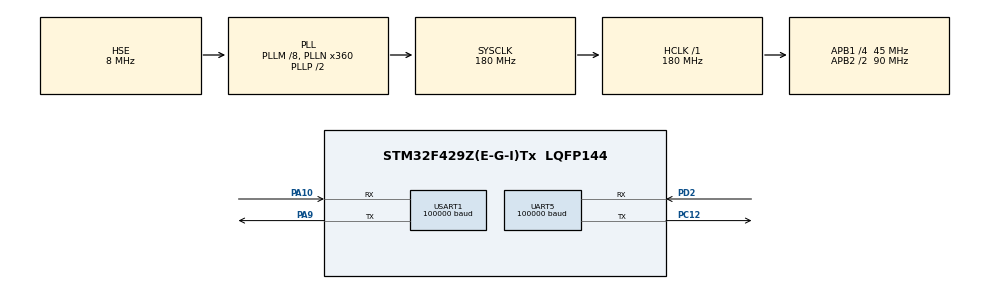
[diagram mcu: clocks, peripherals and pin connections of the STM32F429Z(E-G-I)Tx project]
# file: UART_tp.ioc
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Mcu.Family=STM32F4
Mcu.Name=STM32F429Z(E-G-I)Tx
Mcu.Package=LQFP144
NVIC.PriorityGroup=NVIC_PRIORITYGROUP_4
NVIC.UART5_IRQn=true\:0\:0\:false
NVIC.USART1_IRQn=true\:0\:0\:false
PA10.Mode=Asynchronous
PA10.Signal=USART1_RX
PA9.Mode=Asynchronous
PA9.Signal=USART1_TX
PC12.Mode=Asynchronous
PC12.Signal=UART5_TX
PD2.Mode=Asynchronous
PD2.Signal=UART5_RX
PH0/OSC_IN.Mode=HSE-External-Oscillator
PH0/OSC_IN.Signal=RCC_OSC_IN
PH1/OSC_OUT.Mode=HSE-External-Oscillator
PH1/OSC_OUT.Signal=RCC_OSC_OUT
ProjectManager.TargetToolchain=MDK-ARM V5
RCC.48MHZClocksFreq_Value=90000000
RCC.AHBFreq_Value=180000000
RCC.APB1CLKDivider=RCC_HCLK_DIV4
RCC.APB1Freq_Value=45000000
RCC.APB1TimFreq_Value=90000000
RCC.APB2CLKDivider=RCC_HCLK_DIV2
RCC.APB2Freq_Value=90000000
RCC.APB2TimFreq_Value=180000000
RCC.CortexFreq_Value=180000000
RCC.HCLKFreq_Value=180000000
RCC.HSE_VALUE=8000000
RCC.HSI_VALUE=16000000
RCC.LSE_VALUE=32768
RCC.PLLM=8
RCC.PLLN=360
RCC.PLLSourceVirtual=RCC_PLLSOURCE_HSE
RCC.SYSCLKFreq_VALUE=180000000
RCC.SYSCLKSource=RCC_SYSCLKSOURCE_PLLCLK
RCC.VCOOutputFreq_Value=360000000
UART5.BaudRate=100000
UART5.Parity=UART_PARITY_EVEN
UART5.WordLength=UART_WORDLENGTH_9B
USART1.BaudRate=100000
USART1.Parity=UART_PARITY_EVEN
USART1.WordLength=UART_WORDLENGTH_9B
board=UART_tp

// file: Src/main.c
/**
  ******************************************************************************
  * File Name          : main.c
  * Description        : Main program body
  ******************************************************************************
  *
  * COPYRIGHT(c) 2016 STMicroelectronics
  *
  * Redistribution and use in source and binary forms, with or without modification,
  * are permitted provided that the following conditions are met:
  *   1. Redistributions of source code must retain the above copyright notice,
  *      this list of conditions and the following disclaimer.
  *   2. Redistributions in binary form must reproduce the above copyright notice,
  *      this list of conditions and the following disclaimer in the documentation
  *      and/or other materials provided with the distribution.
  *   3. Neither the name of STMicroelectronics nor the names of its contributors
  *      may be used to endorse or promote products derived from this software
  *      without specific prior written permission.
  *
  * THIS SOFTWARE IS PROVIDED BY THE COPYRIGHT HOLDERS AND CONTRIBUTORS "AS IS"
  * AND ANY EXPRESS OR IMPLIED WARRANTIES, INCLUDING, BUT NOT LIMITED TO, THE
  * IMPLIED WARRANTIES OF MERCHANTABILITY AND FITNESS FOR A PARTICULAR PURPOSE ARE
  * DISCLAIMED. IN NO EVENT SHALL THE COPYRIGHT HOLDER OR CONTRIBUTORS BE LIABLE
  * FOR ANY DIRECT, INDIRECT, INCIDENTAL, SPECIAL, EXEMPLARY, OR CONSEQUENTIAL
  * DAMAGES (INCLUDING, BUT NOT LIMITED TO, PROCUREMENT OF SUBSTITUTE GOODS OR
  * SERVICES; LOSS OF USE, DATA, OR PROFITS; OR BUSINESS INTERRUPTION) HOWEVER
  * CAUSED AND ON ANY THEORY OF LIABILITY, WHETHER IN CONTRACT, STRICT LIABILITY,
  * OR TORT (INCLUDING NEGLIGENCE OR OTHERWISE) ARISING IN ANY WAY OUT OF THE USE
  * OF THIS SOFTWARE, EVEN IF ADVISED OF THE POSSIBILITY OF SUCH DAMAGE.
  *
  ******************************************************************************
  */
#include "stm32f4xx_hal.h"

UART_HandleTypeDef huart5;
UART_HandleTypeDef huart1;

/* USER CODE BEGIN PV */
/* Private variables ---------------------------------------------------------*/

/* USER CODE END PV */

void SystemClock_Config(void);
static void MX_GPIO_Init(void);
static void MX_UART5_Init(void);
static void MX_USART1_UART_Init(void);

#define SIZE 5
uint8_t  UART1_Tx[SIZE] = {0x06, 0x16, 0x26 , 0x36, 0x46} , UART1_Rx[SIZE] , UART5_Tx[SIZE] = {0x09, 0x19, 0x29 , 0x39, 0x49} , UART5_Rx[SIZE] ;
HAL_StatusTypeDef UART1_Tx_Status, UART1_Rx_Status, UART5_Tx_Status, UART5_Rx_Status;
/* USER CODE BEGIN PFP */
/* Private function prototypes -----------------------------------------------*/

/* USER CODE END PFP */

int main(void)
{

  /* MCU Configuration----------------------------------------------------------*/

  /* Reset of all peripherals, Initializes the Flash interface and the Systick. */
  HAL_Init();

  /* Configure the system clock */
  SystemClock_Config();

  /* Initialize all configured peripherals */
  MX_GPIO_Init();
  MX_UART5_Init();
  MX_USART1_UART_Init();

  /* Infinite loop */
  /* USER CODE BEGIN WHILE */

//	HAL_StatusTypeDef HAL_UART_Transmit_IT(UART_HandleTypeDef *huart, uint8_t *pData, uint16_t Size)
//  HAL_StatusTypeDef HAL_UART_Receive_IT(UART_HandleTypeDef *huart, uint8_t *pData, uint16_t Size)

  while (1)
  {
  /* USER CODE END WHILE */

			UART1_Tx_Status = HAL_UART_Transmit_IT(&huart1, UART1_Tx, SIZE);
			UART5_Tx_Status = HAL_UART_Transmit_IT(&huart5, UART5_Tx, SIZE);

		//HAL_GPIO_TogglePin(GPIOG , GPIO_PIN_14);

			HAL_Delay(5);

  }

}

/** System Clock Configuration
*/
void SystemClock_Config(void)
{

  RCC_OscInitTypeDef RCC_OscInitStruct;
  RCC_ClkInitTypeDef RCC_ClkInitStruct;

  __PWR_CLK_ENABLE();

  __HAL_PWR_VOLTAGESCALING_CONFIG(PWR_REGULATOR_VOLTAGE_SCALE1);

  RCC_OscInitStruct.OscillatorType = RCC_OSCILLATORTYPE_HSE;
  RCC_OscInitStruct.HSEState = RCC_HSE_ON;
  RCC_OscInitStruct.PLL.PLLState = RCC_PLL_ON;
  RCC_OscInitStruct.PLL.PLLSource = RCC_PLLSOURCE_HSE;
  RCC_OscInitStruct.PLL.PLLM = 8;
  RCC_OscInitStruct.PLL.PLLN = 360;
  RCC_OscInitStruct.PLL.PLLP = RCC_PLLP_DIV2;
  RCC_OscInitStruct.PLL.PLLQ = 4;
  HAL_RCC_OscConfig(&RCC_OscInitStruct);

  HAL_PWREx_ActivateOverDrive();

  RCC_ClkInitStruct.ClockType = RCC_CLOCKTYPE_SYSCLK|RCC_CLOCKTYPE_PCLK1
                              |RCC_CLOCKTYPE_PCLK2;
  RCC_ClkInitStruct.SYSCLKSource = RCC_SYSCLKSOURCE_PLLCLK;
  RCC_ClkInitStruct.AHBCLKDivider = RCC_SYSCLK_DIV1;
  RCC_ClkInitStruct.APB1CLKDivider = RCC_HCLK_DIV4;
  RCC_ClkInitStruct.APB2CLKDivider = RCC_HCLK_DIV2;
  HAL_RCC_ClockConfig(&RCC_ClkInitStruct, FLASH_LATENCY_5);

  HAL_SYSTICK_Config(HAL_RCC_GetHCLKFreq()/1000);

  HAL_SYSTICK_CLKSourceConfig(SYSTICK_CLKSOURCE_HCLK);

  /* SysTick_IRQn interrupt configuration */
  HAL_NVIC_SetPriority(SysTick_IRQn, 0, 0);
}

/* UART5 init function */
void MX_UART5_Init(void)
{

  huart5.Instance = UART5;
  huart5.Init.BaudRate = 100000;
  huart5.Init.WordLength = UART_WORDLENGTH_9B;
  huart5.Init.StopBits = UART_STOPBITS_1;
  huart5.Init.Parity = UART_PARITY_EVEN;
  huart5.Init.Mode = UART_MODE_TX_RX;
  huart5.Init.HwFlowCtl = UART_HWCONTROL_NONE;
  huart5.Init.OverSampling = UART_OVERSAMPLING_16;
  HAL_UART_Init(&huart5);

}

/* USART1 init function */
void MX_USART1_UART_Init(void)
{

  huart1.Instance = USART1;
  huart1.Init.BaudRate = 100000;
  huart1.Init.WordLength = UART_WORDLENGTH_9B;
  huart1.Init.StopBits = UART_STOPBITS_1;
  huart1.Init.Parity = UART_PARITY_EVEN;
  huart1.Init.Mode = UART_MODE_TX_RX;
  huart1.Init.HwFlowCtl = UART_HWCONTROL_NONE;
  huart1.Init.OverSampling = UART_OVERSAMPLING_16;
  HAL_UART_Init(&huart1);

}

/** Configure pins as
        * Analog
        * Input
        * Output
        * EVENT_OUT
        * EXTI
*/
void MX_GPIO_Init(void)
{

  /* GPIO Ports Clock Enable */
  __GPIOH_CLK_ENABLE();
  __GPIOA_CLK_ENABLE();
  __GPIOC_CLK_ENABLE();
  __GPIOD_CLK_ENABLE();

}

/************************ (C) COPYRIGHT STMicroelectronics *****END OF FILE****/
